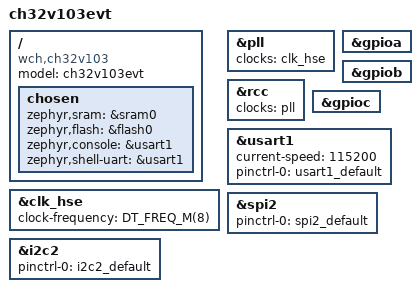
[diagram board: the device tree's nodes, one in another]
/*
 * Copyright (c) 2026 Lucy Wong
 *
 * SPDX-License-Identifier: Apache-2.0
 */

/dts-v1/;

#include <wch/ch32v103/ch32v103c8t6.dtsi>

#include "ch32v103evt-pinctrl.dtsi"

/ {
	model = "ch32v103evt";
	compatible = "wch,ch32v103", "wch,ch32v103c8t6";

	chosen {
		zephyr,sram = &sram0;
		zephyr,flash = &flash0;
		zephyr,console = &usart1;
		zephyr,shell-uart = &usart1;
	};
};

&clk_hse {
	clock-frequency = <DT_FREQ_M(8)>;
	status = "okay";
};

&pll {
	clocks = <&clk_hse>;
	status = "okay";
};

&rcc {
	clocks = <&pll>;
};

&gpioa {
	status = "okay";
};

&gpiob {
	status = "okay";
};

&gpioc {
	status = "okay";
};

&usart1 {
	status = "okay";
	current-speed = <115200>;
	pinctrl-0 = <&usart1_default>;
	pinctrl-names = "default";
};

&spi2 {
	pinctrl-0 = <&spi2_default>;
	pinctrl-names = "default";
};

&i2c2 {
	pinctrl-0 = <&i2c2_default>;
	pinctrl-names = "default";
};
